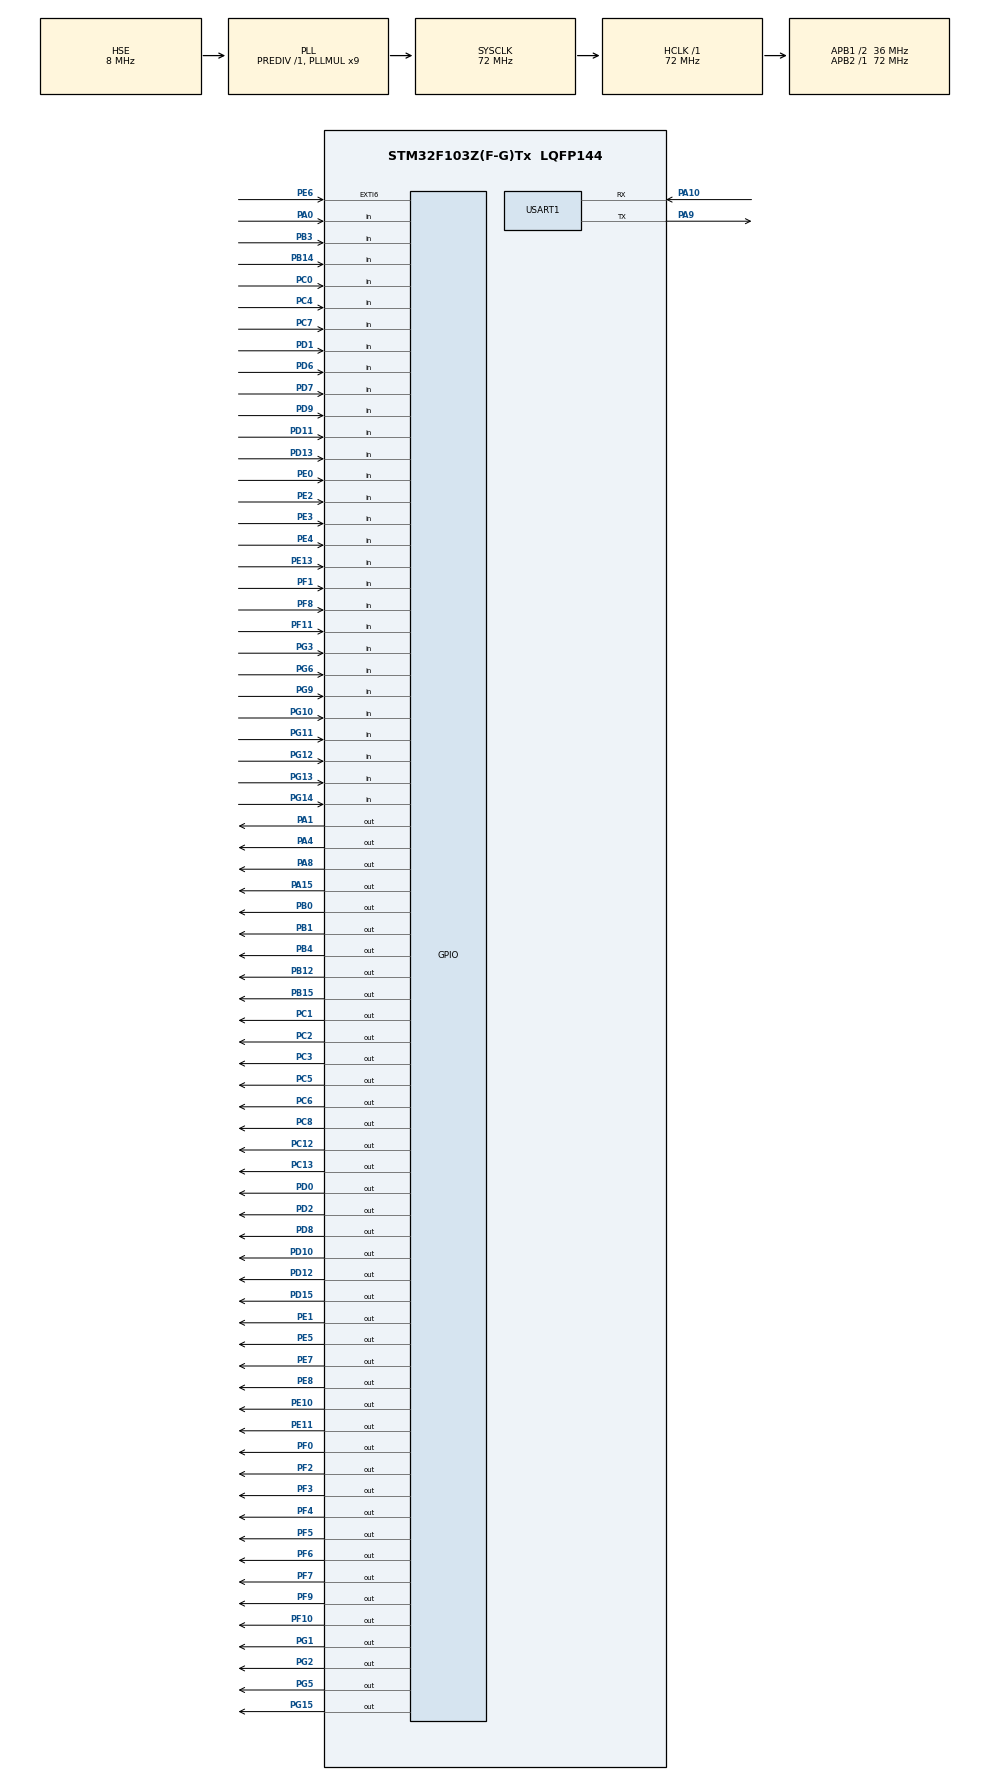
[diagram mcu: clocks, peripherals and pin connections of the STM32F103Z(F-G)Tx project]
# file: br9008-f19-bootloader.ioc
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Mcu.Family=STM32F1
Mcu.Name=STM32F103Z(F-G)Tx
Mcu.Package=LQFP144
NVIC.PriorityGroup=NVIC_PRIORITYGROUP_4
OSC_IN.Mode=HSE-External-Oscillator
OSC_IN.Signal=RCC_OSC_IN
OSC_OUT.Mode=HSE-External-Oscillator
OSC_OUT.Signal=RCC_OSC_OUT
PA0-WKUP.GPIO_PuPd=GPIO_PULLUP
PA0-WKUP.Signal=GPIO_Input
PA1.Signal=GPIO_Output
PA10.Mode=Asynchronous
PA10.Signal=USART1_RX
PA13.Mode=Serial_Wire
PA13.Signal=SYS_JTMS-SWDIO
PA14.Mode=Serial_Wire
PA14.Signal=SYS_JTCK-SWCLK
PA15.Signal=GPIO_Output
PA4.Signal=GPIO_Output
PA5.Signal=SPI1_SCK
PA6.Signal=SPI1_MISO
PA7.Signal=SPI1_MOSI
PA8.Signal=GPIO_Output
PA9.Mode=Asynchronous
PA9.Signal=USART1_TX
PB0.Signal=GPIO_Output
PB1.Signal=GPIO_Output
PB10.Signal=I2C2_SCL
PB11.Signal=I2C2_SDA
PB12.GPIO_PuPd=GPIO_PULLDOWN
PB12.Signal=GPIO_Output
PB14.Signal=GPIO_Input
PB15.Signal=GPIO_Output
PB3.GPIO_PuPd=GPIO_PULLUP
PB3.Signal=GPIO_Input
PB4.Signal=GPIO_Output
PB6.Signal=I2C1_SCL
PB7.Signal=I2C1_SDA
PB8.Signal=CAN_RX
PB9.Signal=CAN_TX
PC0.Signal=GPIO_Input
PC1.Signal=GPIO_Output
PC12.GPIO_PuPd=GPIO_PULLDOWN
PC12.Signal=GPIO_Output
PC13-TAMPER-RTC.Signal=GPIO_Output
PC2.Signal=GPIO_Output
PC3.Signal=GPIO_Output
PC4.GPIO_PuPd=GPIO_PULLUP
PC4.Signal=GPIO_Input
PC5.Signal=GPIO_Output
PC6.Signal=GPIO_Output
PC7.Signal=GPIO_Input
PC8.Signal=GPIO_Output
PD0.GPIO_PuPd=GPIO_PULLDOWN
PD0.Signal=GPIO_Output
PD1.Signal=GPIO_Input
PD10.GPIO_PuPd=GPIO_PULLDOWN
PD10.Signal=GPIO_Output
PD11.Signal=GPIO_Input
PD12.GPIO_PuPd=GPIO_PULLDOWN
PD12.Signal=GPIO_Output
PD13.Signal=GPIO_Input
PD15.Signal=GPIO_Output
PD2.Signal=GPIO_Output
PD6.GPIO_PuPd=GPIO_PULLUP
PD6.Signal=GPIO_Input
PD7.Signal=GPIO_Input
PD8.GPIO_ModeDefaultOutputPP=GPIO_MODE_OUTPUT_OD
PD8.GPIO_PuPd=GPIO_PULLUP
PD8.GPIO_Speed=GPIO_SPEED_FREQ_HIGH
PD8.PinState=GPIO_PIN_SET
PD8.Signal=GPIO_Output
PD9.Signal=GPIO_Input
PE0.GPIO_PuPd=GPIO_PULLUP
PE0.Signal=GPIO_Input
PE1.Signal=GPIO_Output
PE10.GPIO_PuPd=GPIO_PULLDOWN
PE10.Signal=GPIO_Output
PE11.GPIO_PuPd=GPIO_PULLDOWN
PE11.Signal=GPIO_Output
PE13.Signal=GPIO_Input
PE2.Signal=GPIO_Input
PE3.Signal=GPIO_Input
PE4.GPIO_PuPd=GPIO_PULLUP
PE4.Signal=GPIO_Input
PE5.Signal=GPIO_Output
PE6.GPIO_PuPd=GPIO_PULLUP
PE6.Signal=GPXTI6
PE7.Signal=GPIO_Output
PE8.GPIO_ModeDefaultOutputPP=GPIO_MODE_OUTPUT_PP
PE8.GPIO_PuPd=GPIO_PULLDOWN
PE8.Signal=GPIO_Output
PF0.Signal=GPIO_Output
PF1.GPIO_PuPd=GPIO_PULLUP
PF1.Signal=GPIO_Input
PF10.GPIO_PuPd=GPIO_PULLDOWN
PF10.Signal=GPIO_Output
PF11.GPIO_PuPd=GPIO_PULLUP
PF11.Signal=GPIO_Input
PF2.Signal=GPIO_Output
PF3.Signal=GPIO_Output
PF4.Signal=GPIO_Output
PF5.GPIO_PuPd=GPIO_PULLDOWN
PF5.Signal=GPIO_Output
PF6.GPIO_ModeDefaultOutputPP=GPIO_MODE_OUTPUT_OD
PF6.GPIO_PuPd=GPIO_PULLUP
PF6.GPIO_Speed=GPIO_SPEED_FREQ_HIGH
PF6.PinState=GPIO_PIN_SET
PF6.Signal=GPIO_Output
PF7.GPIO_PuPd=GPIO_PULLDOWN
PF7.Signal=GPIO_Output
PF8.Signal=GPIO_Input
PF9.GPIO_PuPd=GPIO_PULLDOWN
PF9.Signal=GPIO_Output
PG1.Signal=GPIO_Output
PG10.Signal=GPIO_Input
PG11.Signal=GPIO_Input
PG12.Signal=GPIO_Input
PG13.GPIO_PuPd=GPIO_PULLUP
PG13.Signal=GPIO_Input
PG14.Signal=GPIO_Input
PG15.Signal=GPIO_Output
PG2.GPIO_PuPd=GPIO_PULLDOWN
PG2.Signal=GPIO_Output
PG3.GPIO_PuPd=GPIO_PULLUP
PG3.Signal=GPIO_Input
PG5.Signal=GPIO_Output
PG6.Signal=GPIO_Input
PG9.Signal=GPIO_Input
ProjectManager.HeapSize=0x200
ProjectManager.StackSize=0x400
ProjectManager.TargetToolchain=MDK-ARM V5.32
RCC.AHBFreq_Value=72000000
RCC.APB1CLKDivider=RCC_HCLK_DIV2
RCC.APB1Freq_Value=36000000
RCC.APB1TimFreq_Value=72000000
RCC.APB2Freq_Value=72000000
RCC.APB2TimFreq_Value=72000000
RCC.HCLKFreq_Value=72000000
RCC.PLLMUL=RCC_PLL_MUL9
RCC.PLLSourceVirtual=RCC_PLLSOURCE_HSE
RCC.RTCClockSelection=RCC_RTCCLKSOURCE_LSE
RCC.SYSCLKFreq_VALUE=72000000
RCC.SYSCLKSource=RCC_SYSCLKSOURCE_PLLCLK
RCC.USBFreq_Value=48000000
RCC.USBPrescaler=RCC_USBCLKSOURCE_PLL_DIV1_5
USART1.VirtualMode=VM_ASYNC
board=custom

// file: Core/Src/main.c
/* USER CODE BEGIN Header */
/**
  ******************************************************************************
  * @file           : main.c
  * @brief          : Main program body
  ******************************************************************************
  * @attention
  *
  * Copyright (c) 2025 STMicroelectronics.
  * All rights reserved.
  *
  * This software is licensed under terms that can be found in the LICENSE file
  * in the root directory of this software component.
  * If no LICENSE file comes with this software, it is provided AS-IS.
  *
  ******************************************************************************
  */
/* USER CODE END Header */
#include "main.h"

/* USER CODE BEGIN Includes */
#include "board.h"
/* USER CODE END Includes */

UART_HandleTypeDef huart1;

void SystemClock_Config(void);
static void MX_GPIO_Init(void);
static void MX_USART1_UART_Init(void);

int main(void)
{

  /* MCU Configuration--------------------------------------------------------*/

  /* Reset of all peripherals, Initializes the Flash interface and the Systick. */
  HAL_Init();

  /* Configure the system clock */
  SystemClock_Config();

  /* Initialize all configured peripherals */
  MX_GPIO_Init();
  MX_USART1_UART_Init();

  /* Infinite loop */
  /* USER CODE BEGIN WHILE */
  board_init();
  while (1)
  {
    /* USER CODE END WHILE */
	board_handler();
  }
}

void SystemClock_Config(void)
{
  RCC_OscInitTypeDef RCC_OscInitStruct = {0};
  RCC_ClkInitTypeDef RCC_ClkInitStruct = {0};

  /** Initializes the RCC Oscillators according to the specified parameters
  * in the RCC_OscInitTypeDef structure.
  */
  RCC_OscInitStruct.OscillatorType = RCC_OSCILLATORTYPE_HSE;
  RCC_OscInitStruct.HSEState = RCC_HSE_ON;
  RCC_OscInitStruct.HSEPredivValue = RCC_HSE_PREDIV_DIV1;
  RCC_OscInitStruct.HSIState = RCC_HSI_ON;
  RCC_OscInitStruct.PLL.PLLState = RCC_PLL_ON;
  RCC_OscInitStruct.PLL.PLLSource = RCC_PLLSOURCE_HSE;
  RCC_OscInitStruct.PLL.PLLMUL = RCC_PLL_MUL9;
  if (HAL_RCC_OscConfig(&RCC_OscInitStruct) != HAL_OK)
  {
    Error_Handler();
  }

  /** Initializes the CPU, AHB and APB buses clocks
  */
  RCC_ClkInitStruct.ClockType = RCC_CLOCKTYPE_HCLK|RCC_CLOCKTYPE_SYSCLK
                              |RCC_CLOCKTYPE_PCLK1|RCC_CLOCKTYPE_PCLK2;
  RCC_ClkInitStruct.SYSCLKSource = RCC_SYSCLKSOURCE_PLLCLK;
  RCC_ClkInitStruct.AHBCLKDivider = RCC_SYSCLK_DIV1;
  RCC_ClkInitStruct.APB1CLKDivider = RCC_HCLK_DIV2;
  RCC_ClkInitStruct.APB2CLKDivider = RCC_HCLK_DIV1;

  if (HAL_RCC_ClockConfig(&RCC_ClkInitStruct, FLASH_LATENCY_2) != HAL_OK)
  {
    Error_Handler();
  }
}

static void MX_USART1_UART_Init(void)
{

  huart1.Instance = USART1;
  huart1.Init.BaudRate = 115200;
  huart1.Init.WordLength = UART_WORDLENGTH_8B;
  huart1.Init.StopBits = UART_STOPBITS_1;
  huart1.Init.Parity = UART_PARITY_NONE;
  huart1.Init.Mode = UART_MODE_TX_RX;
  huart1.Init.HwFlowCtl = UART_HWCONTROL_NONE;
  huart1.Init.OverSampling = UART_OVERSAMPLING_16;
  if (HAL_UART_Init(&huart1) != HAL_OK)
  {
    Error_Handler();
  }

}

static void MX_GPIO_Init(void)
{
  GPIO_InitTypeDef GPIO_InitStruct = {0};

  /* GPIO Ports Clock Enable */
  __HAL_RCC_GPIOE_CLK_ENABLE();
  __HAL_RCC_GPIOC_CLK_ENABLE();
  __HAL_RCC_GPIOF_CLK_ENABLE();
  __HAL_RCC_GPIOA_CLK_ENABLE();
  __HAL_RCC_GPIOB_CLK_ENABLE();
  __HAL_RCC_GPIOG_CLK_ENABLE();
  __HAL_RCC_GPIOD_CLK_ENABLE();

  /*Configure GPIO pin Output Level */
  HAL_GPIO_WritePin(GPIOE, GPIO_PIN_5|GPIO_PIN_7|GPIO_PIN_8|GPIO_PIN_10
                          |GPIO_PIN_11|GPIO_PIN_1, GPIO_PIN_RESET);

  /*Configure GPIO pin Output Level */
  HAL_GPIO_WritePin(GPIOC, GPIO_PIN_13|GPIO_PIN_1|GPIO_PIN_2|GPIO_PIN_3
                          |GPIO_PIN_5|GPIO_PIN_6|GPIO_PIN_8|GPIO_PIN_12, GPIO_PIN_RESET);

  /*Configure GPIO pin Output Level */
  HAL_GPIO_WritePin(GPIOF, GPIO_PIN_0|GPIO_PIN_2|GPIO_PIN_3|GPIO_PIN_4
                          |GPIO_PIN_5|GPIO_PIN_7|GPIO_PIN_9|GPIO_PIN_10, GPIO_PIN_RESET);

  /*Configure GPIO pin Output Level */
  HAL_GPIO_WritePin(GPIOF, GPIO_PIN_6, GPIO_PIN_SET);

  /*Configure GPIO pin Output Level */
  HAL_GPIO_WritePin(GPIOA, GPIO_PIN_1|GPIO_PIN_4|GPIO_PIN_8|GPIO_PIN_15, GPIO_PIN_RESET);

  /*Configure GPIO pin Output Level */
  HAL_GPIO_WritePin(GPIOB, GPIO_PIN_0|GPIO_PIN_1|GPIO_PIN_12|GPIO_PIN_15
                          |GPIO_PIN_4, GPIO_PIN_RESET);

  /*Configure GPIO pin Output Level */
  HAL_GPIO_WritePin(GPIOG, GPIO_PIN_1|GPIO_PIN_2|GPIO_PIN_5|GPIO_PIN_15, GPIO_PIN_RESET);

  /*Configure GPIO pin Output Level */
  HAL_GPIO_WritePin(GPIOD, GPIO_PIN_8, GPIO_PIN_SET);

  /*Configure GPIO pin Output Level */
  HAL_GPIO_WritePin(GPIOD, GPIO_PIN_10|GPIO_PIN_12|GPIO_PIN_15|GPIO_PIN_0
                          |GPIO_PIN_2, GPIO_PIN_RESET);

  /*Configure GPIO pins : PE2 PE3 PE13 */
  GPIO_InitStruct.Pin = GPIO_PIN_2|GPIO_PIN_3|GPIO_PIN_13;
  GPIO_InitStruct.Mode = GPIO_MODE_INPUT;
  GPIO_InitStruct.Pull = GPIO_NOPULL;
  HAL_GPIO_Init(GPIOE, &GPIO_InitStruct);

  /*Configure GPIO pins : PE4 PE0 */
  GPIO_InitStruct.Pin = GPIO_PIN_4|GPIO_PIN_0;
  GPIO_InitStruct.Mode = GPIO_MODE_INPUT;
  GPIO_InitStruct.Pull = GPIO_PULLUP;
  HAL_GPIO_Init(GPIOE, &GPIO_InitStruct);

  /*Configure GPIO pins : PE5 PE7 PE1 */
  GPIO_InitStruct.Pin = GPIO_PIN_5|GPIO_PIN_7|GPIO_PIN_1;
  GPIO_InitStruct.Mode = GPIO_MODE_OUTPUT_PP;
  GPIO_InitStruct.Pull = GPIO_NOPULL;
  GPIO_InitStruct.Speed = GPIO_SPEED_FREQ_LOW;
  HAL_GPIO_Init(GPIOE, &GPIO_InitStruct);

  /*Configure GPIO pin : PE6 */
  GPIO_InitStruct.Pin = GPIO_PIN_6;
  GPIO_InitStruct.Mode = GPIO_MODE_IT_RISING;
  GPIO_InitStruct.Pull = GPIO_PULLUP;
  HAL_GPIO_Init(GPIOE, &GPIO_InitStruct);

  /*Configure GPIO pins : PC13 PC1 PC2 PC3
                           PC5 PC6 PC8 */
  GPIO_InitStruct.Pin = GPIO_PIN_13|GPIO_PIN_1|GPIO_PIN_2|GPIO_PIN_3
                          |GPIO_PIN_5|GPIO_PIN_6|GPIO_PIN_8;
  GPIO_InitStruct.Mode = GPIO_MODE_OUTPUT_PP;
  GPIO_InitStruct.Pull = GPIO_NOPULL;
  GPIO_InitStruct.Speed = GPIO_SPEED_FREQ_LOW;
  HAL_GPIO_Init(GPIOC, &GPIO_InitStruct);

  /*Configure GPIO pins : PF0 PF2 PF3 PF4 */
  GPIO_InitStruct.Pin = GPIO_PIN_0|GPIO_PIN_2|GPIO_PIN_3|GPIO_PIN_4;
  GPIO_InitStruct.Mode = GPIO_MODE_OUTPUT_PP;
  GPIO_InitStruct.Pull = GPIO_NOPULL;
  GPIO_InitStruct.Speed = GPIO_SPEED_FREQ_LOW;
  HAL_GPIO_Init(GPIOF, &GPIO_InitStruct);

  /*Configure GPIO pins : PF1 PF11 */
  GPIO_InitStruct.Pin = GPIO_PIN_1|GPIO_PIN_11;
  GPIO_InitStruct.Mode = GPIO_MODE_INPUT;
  GPIO_InitStruct.Pull = GPIO_PULLUP;
  HAL_GPIO_Init(GPIOF, &GPIO_InitStruct);

  /*Configure GPIO pins : PF5 PF7 PF9 PF10 */
  GPIO_InitStruct.Pin = GPIO_PIN_5|GPIO_PIN_7|GPIO_PIN_9|GPIO_PIN_10;
  GPIO_InitStruct.Mode = GPIO_MODE_OUTPUT_PP;
  GPIO_InitStruct.Pull = GPIO_PULLDOWN;
  GPIO_InitStruct.Speed = GPIO_SPEED_FREQ_LOW;
  HAL_GPIO_Init(GPIOF, &GPIO_InitStruct);

  /*Configure GPIO pin : PF6 */
  GPIO_InitStruct.Pin = GPIO_PIN_6;
  GPIO_InitStruct.Mode = GPIO_MODE_OUTPUT_OD;
  GPIO_InitStruct.Pull = GPIO_PULLUP;
  GPIO_InitStruct.Speed = GPIO_SPEED_FREQ_HIGH;
  HAL_GPIO_Init(GPIOF, &GPIO_InitStruct);

  /*Configure GPIO pin : PF8 */
  GPIO_InitStruct.Pin = GPIO_PIN_8;
  GPIO_InitStruct.Mode = GPIO_MODE_INPUT;
  GPIO_InitStruct.Pull = GPIO_NOPULL;
  HAL_GPIO_Init(GPIOF, &GPIO_InitStruct);

  /*Configure GPIO pins : PC0 PC7 */
  GPIO_InitStruct.Pin = GPIO_PIN_0|GPIO_PIN_7;
  GPIO_InitStruct.Mode = GPIO_MODE_INPUT;
  GPIO_InitStruct.Pull = GPIO_NOPULL;
  HAL_GPIO_Init(GPIOC, &GPIO_InitStruct);

  /*Configure GPIO pin : PA0 */
  GPIO_InitStruct.Pin = GPIO_PIN_0;
  GPIO_InitStruct.Mode = GPIO_MODE_INPUT;
  GPIO_InitStruct.Pull = GPIO_PULLUP;
  HAL_GPIO_Init(GPIOA, &GPIO_InitStruct);

  /*Configure GPIO pins : PA1 PA4 PA8 PA15 */
  GPIO_InitStruct.Pin = GPIO_PIN_1|GPIO_PIN_4|GPIO_PIN_8|GPIO_PIN_15;
  GPIO_InitStruct.Mode = GPIO_MODE_OUTPUT_PP;
  GPIO_InitStruct.Pull = GPIO_NOPULL;
  GPIO_InitStruct.Speed = GPIO_SPEED_FREQ_LOW;
  HAL_GPIO_Init(GPIOA, &GPIO_InitStruct);

  /*Configure GPIO pins : PA5 PA6 PA7 */
  GPIO_InitStruct.Pin = GPIO_PIN_5|GPIO_PIN_6|GPIO_PIN_7;
  GPIO_InitStruct.Mode = GPIO_MODE_AF_PP;
  GPIO_InitStruct.Speed = GPIO_SPEED_FREQ_HIGH;
  HAL_GPIO_Init(GPIOA, &GPIO_InitStruct);

  /*Configure GPIO pin : PC4 */
  GPIO_InitStruct.Pin = GPIO_PIN_4;
  GPIO_InitStruct.Mode = GPIO_MODE_INPUT;
  GPIO_InitStruct.Pull = GPIO_PULLUP;
  HAL_GPIO_Init(GPIOC, &GPIO_InitStruct);

  /*Configure GPIO pins : PB0 PB1 PB15 PB4 */
  GPIO_InitStruct.Pin = GPIO_PIN_0|GPIO_PIN_1|GPIO_PIN_15|GPIO_PIN_4;
  GPIO_InitStruct.Mode = GPIO_MODE_OUTPUT_PP;
  GPIO_InitStruct.Pull = GPIO_NOPULL;
  GPIO_InitStruct.Speed = GPIO_SPEED_FREQ_LOW;
  HAL_GPIO_Init(GPIOB, &GPIO_InitStruct);

  /*Configure GPIO pins : PG1 PG5 PG15 */
  GPIO_InitStruct.Pin = GPIO_PIN_1|GPIO_PIN_5|GPIO_PIN_15;
  GPIO_InitStruct.Mode = GPIO_MODE_OUTPUT_PP;
  GPIO_InitStruct.Pull = GPIO_NOPULL;
  GPIO_InitStruct.Speed = GPIO_SPEED_FREQ_LOW;
  HAL_GPIO_Init(GPIOG, &GPIO_InitStruct);

  /*Configure GPIO pins : PE8 PE10 PE11 */
  GPIO_InitStruct.Pin = GPIO_PIN_8|GPIO_PIN_10|GPIO_PIN_11;
  GPIO_InitStruct.Mode = GPIO_MODE_OUTPUT_PP;
  GPIO_InitStruct.Pull = GPIO_PULLDOWN;
  GPIO_InitStruct.Speed = GPIO_SPEED_FREQ_LOW;
  HAL_GPIO_Init(GPIOE, &GPIO_InitStruct);

  /*Configure GPIO pins : PB10 PB11 PB6 PB7 */
  GPIO_InitStruct.Pin = GPIO_PIN_10|GPIO_PIN_11|GPIO_PIN_6|GPIO_PIN_7;
  GPIO_InitStruct.Mode = GPIO_MODE_AF_OD;
  GPIO_InitStruct.Speed = GPIO_SPEED_FREQ_HIGH;
  HAL_GPIO_Init(GPIOB, &GPIO_InitStruct);

  /*Configure GPIO pin : PB12 */
  GPIO_InitStruct.Pin = GPIO_PIN_12;
  GPIO_InitStruct.Mode = GPIO_MODE_OUTPUT_PP;
  GPIO_InitStruct.Pull = GPIO_PULLDOWN;
  GPIO_InitStruct.Speed = GPIO_SPEED_FREQ_LOW;
  HAL_GPIO_Init(GPIOB, &GPIO_InitStruct);

  /*Configure GPIO pin : PB14 */
  GPIO_InitStruct.Pin = GPIO_PIN_14;
  GPIO_InitStruct.Mode = GPIO_MODE_INPUT;
  GPIO_InitStruct.Pull = GPIO_NOPULL;
  HAL_GPIO_Init(GPIOB, &GPIO_InitStruct);

  /*Configure GPIO pin : PD8 */
  GPIO_InitStruct.Pin = GPIO_PIN_8;
  GPIO_InitStruct.Mode = GPIO_MODE_OUTPUT_OD;
  GPIO_InitStruct.Pull = GPIO_PULLUP;
  GPIO_InitStruct.Speed = GPIO_SPEED_FREQ_HIGH;
  HAL_GPIO_Init(GPIOD, &GPIO_InitStruct);

  /*Configure GPIO pins : PD9 PD11 PD13 PD1
                           PD7 */
  GPIO_InitStruct.Pin = GPIO_PIN_9|GPIO_PIN_11|GPIO_PIN_13|GPIO_PIN_1
                          |GPIO_PIN_7;
  GPIO_InitStruct.Mode = GPIO_MODE_INPUT;
  GPIO_InitStruct.Pull = GPIO_NOPULL;
  HAL_GPIO_Init(GPIOD, &GPIO_InitStruct);

  /*Configure GPIO pins : PD10 PD12 PD0 */
  GPIO_InitStruct.Pin = GPIO_PIN_10|GPIO_PIN_12|GPIO_PIN_0;
  GPIO_InitStruct.Mode = GPIO_MODE_OUTPUT_PP;
  GPIO_InitStruct.Pull = GPIO_PULLDOWN;
  GPIO_InitStruct.Speed = GPIO_SPEED_FREQ_LOW;
  HAL_GPIO_Init(GPIOD, &GPIO_InitStruct);

  /*Configure GPIO pins : PD15 PD2 */
  GPIO_InitStruct.Pin = GPIO_PIN_15|GPIO_PIN_2;
  GPIO_InitStruct.Mode = GPIO_MODE_OUTPUT_PP;
  GPIO_InitStruct.Pull = GPIO_NOPULL;
  GPIO_InitStruct.Speed = GPIO_SPEED_FREQ_LOW;
  HAL_GPIO_Init(GPIOD, &GPIO_InitStruct);

  /*Configure GPIO pin : PG2 */
  GPIO_InitStruct.Pin = GPIO_PIN_2;
  GPIO_InitStruct.Mode = GPIO_MODE_OUTPUT_PP;
  GPIO_InitStruct.Pull = GPIO_PULLDOWN;
  GPIO_InitStruct.Speed = GPIO_SPEED_FREQ_LOW;
  HAL_GPIO_Init(GPIOG, &GPIO_InitStruct);

  /*Configure GPIO pins : PG3 PG13 */
  GPIO_InitStruct.Pin = GPIO_PIN_3|GPIO_PIN_13;
  GPIO_InitStruct.Mode = GPIO_MODE_INPUT;
  GPIO_InitStruct.Pull = GPIO_PULLUP;
  HAL_GPIO_Init(GPIOG, &GPIO_InitStruct);

  /*Configure GPIO pins : PG6 PG9 PG10 PG11
                           PG12 PG14 */
  GPIO_InitStruct.Pin = GPIO_PIN_6|GPIO_PIN_9|GPIO_PIN_10|GPIO_PIN_11
                          |GPIO_PIN_12|GPIO_PIN_14;
  GPIO_InitStruct.Mode = GPIO_MODE_INPUT;
  GPIO_InitStruct.Pull = GPIO_NOPULL;
  HAL_GPIO_Init(GPIOG, &GPIO_InitStruct);

  /*Configure GPIO pin : PC12 */
  GPIO_InitStruct.Pin = GPIO_PIN_12;
  GPIO_InitStruct.Mode = GPIO_MODE_OUTPUT_PP;
  GPIO_InitStruct.Pull = GPIO_PULLDOWN;
  GPIO_InitStruct.Speed = GPIO_SPEED_FREQ_LOW;
  HAL_GPIO_Init(GPIOC, &GPIO_InitStruct);

  /*Configure GPIO pin : PD6 */
  GPIO_InitStruct.Pin = GPIO_PIN_6;
  GPIO_InitStruct.Mode = GPIO_MODE_INPUT;
  GPIO_InitStruct.Pull = GPIO_PULLUP;
  HAL_GPIO_Init(GPIOD, &GPIO_InitStruct);

  /*Configure GPIO pin : PB3 */
  GPIO_InitStruct.Pin = GPIO_PIN_3;
  GPIO_InitStruct.Mode = GPIO_MODE_INPUT;
  GPIO_InitStruct.Pull = GPIO_PULLUP;
  HAL_GPIO_Init(GPIOB, &GPIO_InitStruct);

  /*Configure GPIO pin : PB8 */
  GPIO_InitStruct.Pin = GPIO_PIN_8;
  GPIO_InitStruct.Mode = GPIO_MODE_INPUT;
  GPIO_InitStruct.Pull = GPIO_NOPULL;
  HAL_GPIO_Init(GPIOB, &GPIO_InitStruct);

  /*Configure GPIO pin : PB9 */
  GPIO_InitStruct.Pin = GPIO_PIN_9;
  GPIO_InitStruct.Mode = GPIO_MODE_AF_PP;
  GPIO_InitStruct.Speed = GPIO_SPEED_FREQ_HIGH;
  HAL_GPIO_Init(GPIOB, &GPIO_InitStruct);

  /*Configure peripheral I/O remapping */
  __HAL_AFIO_REMAP_CAN1_2();

}

void Error_Handler(void)
{
  __disable_irq();
  while (1)
  {
  }
}
